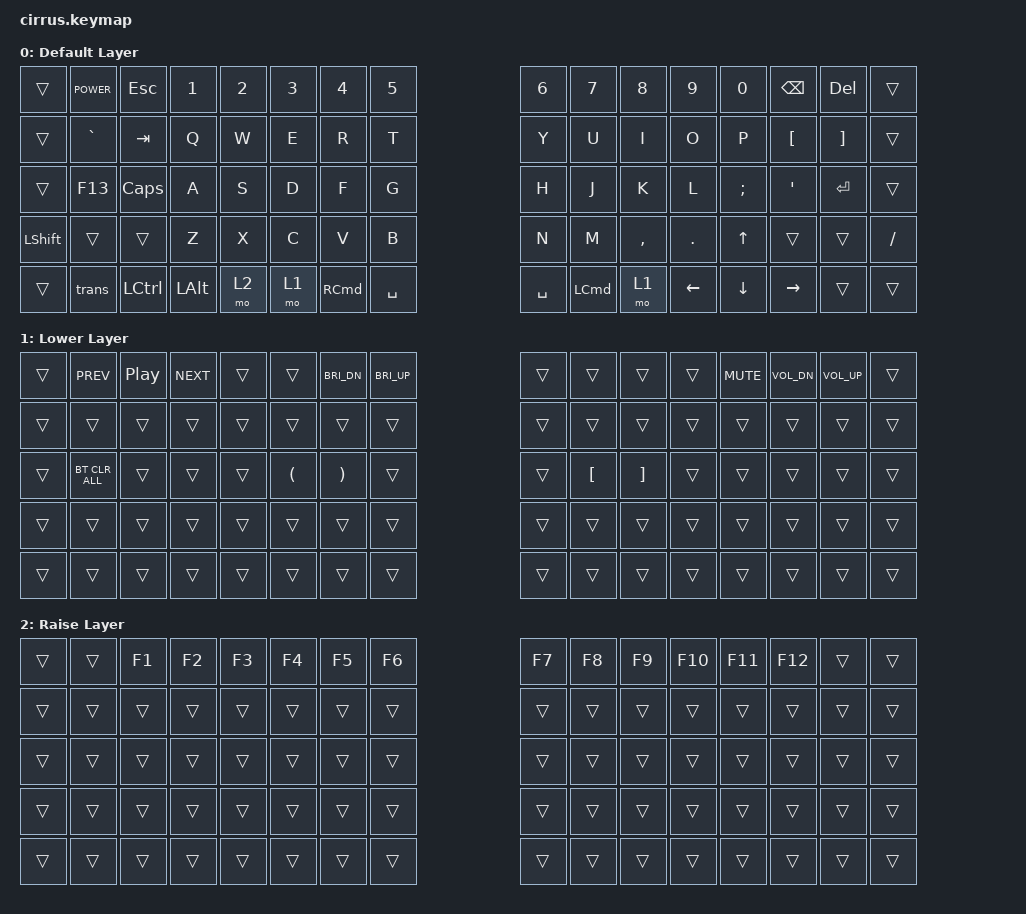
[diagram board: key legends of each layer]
/*
 * Copyright (c) 2020 The ZMK Contributors
 *
 * SPDX-License-Identifier: MIT
 */

#include <behaviors.dtsi>
#include <dt-bindings/zmk/keys.h>
#include <dt-bindings/zmk/bt.h>

/ {
        keymap {
                compatible = "zmk,keymap";

                default_layer {
                        display-name = "Default Layer";



                        bindings = <
   &trans       &kp K_POWER  &kp ESC      &kp N1   &kp N2 &kp N3  &kp N4    &kp N5                       &kp N6     &kp N7      &kp N8    &kp N9    &kp N0     &kp BSPC    &kp DEL     &trans            
   &trans       &kp GRAVE    &kp TAB      &kp Q    &kp W  &kp E   &kp R     &kp T                        &kp Y      &kp U       &kp I     &kp O     &kp P      &kp LBKT    &kp RBKT    &trans 
   &trans       &kp F13      &kp CAPS     &kp A    &kp S  &kp D   &kp F     &kp G                        &kp H      &kp J       &kp K     &kp L     &kp SEMI   &kp SQT     &kp ENTER   &trans 
   &kp LSHIFT   &trans       &trans       &kp Z    &kp X  &kp C   &kp V     &kp B                        &kp N      &kp M       &kp COMMA &kp DOT   &kp UP     &trans      &trans      &kp FSLH 
   &trans       trans       &kp LCTRL    &kp LALT &mo 2  &mo 1   &kp RCMD  &kp SPACE                    &kp SPACE  &kp LCMD    &mo 1     &kp LEFT  &kp DOWN   &kp RIGHT   &trans      &trans
                        >;
                };
                lower_layer {
                        display-name = "Lower Layer";
//COMMAND LAYER

                        bindings = <
   &trans       &kp C_PREV       &kp C_PLAY_PAUSE       &kp C_NEXT   &trans       &trans       &kp C_BRI_DN  &kp C_BRI_UP             &trans       &trans       &trans       &trans       &kp C_MUTE   &kp C_VOL_DN    &kp C_VOL_UP    &trans
   &trans       &trans           &trans                 &trans       &trans       &trans       &trans        &trans                   &trans       &trans       &trans       &trans       &trans       &trans          &trans          &trans
   &trans       &bt BT_CLR_ALL   &trans                 &trans       &trans       &kp LPAR     &kp RPAR      &trans                   &trans       &kp LBKT     &kp RBKT     &trans       &trans       &trans          &trans          &trans
   &trans       &trans           &trans                 &trans       &trans       &trans       &trans        &trans                   &trans       &trans       &trans       &trans       &trans       &trans          &trans          &trans
   &trans       &trans           &trans                 &trans       &trans       &trans       &trans        &trans                   &trans       &trans       &trans       &trans       &trans       &trans          &trans          &trans
                        >;
                };
//FUNCTION LAYER
                raise_layer {
                        display-name = "Raise Layer";
// -----------------------------------------------------------------------------------------
// |  TAB |  !  |  @  |  #  |  $  |  %  |   |  ^  |  &  |  *  |  (  |  )  | BSPC |
// | CTRL |     |     |     |     |     |   |  -  |  =  |  [  |  ]  |  \  |  `   |
// | SHFT |     |     |     |     |     |   |  _  |  +  |  {  |  }  | "|" |  ~   |
//                    | GUI |     | SPC |   | ENT |     | ALT |
                        bindings = <
   &trans       &trans             &kp F1      &kp F2       &kp F3       &kp F4       &kp F5       &kp F6                   &kp F7       &kp F8       &kp F9       &kp F10      &kp F11      &kp F12      &trans       &trans
   &trans       &trans             &trans      &trans       &trans       &trans       &trans       &trans                   &trans       &trans       &trans       &trans       &trans       &trans       &trans       &trans
   &trans       &trans             &trans      &trans       &trans       &trans       &trans       &trans                   &trans       &trans       &trans       &trans       &trans       &trans       &trans       &trans
   &trans       &trans             &trans      &trans       &trans       &trans       &trans       &trans                   &trans       &trans       &trans       &trans       &trans       &trans       &trans       &trans
   &trans       &trans             &trans      &trans       &trans       &trans       &trans       &trans                   &trans       &trans       &trans       &trans       &trans       &trans       &trans       &trans
                        >;
                };
        };
};
